# NANO103AE_v1 register map
File version: 1.0
Registers are 32-bit, read-write, reset 0x0 unless marked. A register's access mark holds for its fields unless they carry their own. Offsets are from the block's base; [hi:lo] are bit positions; {n}, {i} and the like mark numbered series; 'fields as' and 'values as' point back to an identical list.

## SYS — SYS Register Map
Base 0x50000000
0x00 SYS_PDID ro reset 0x110000 (reset mask 0xFFFF0000) — Part Device Identification Number Register
  [31:0] PDID — Part Device Identification Number (Read Only). This register reflects device part number code. Software can read this register to identify which device is used.
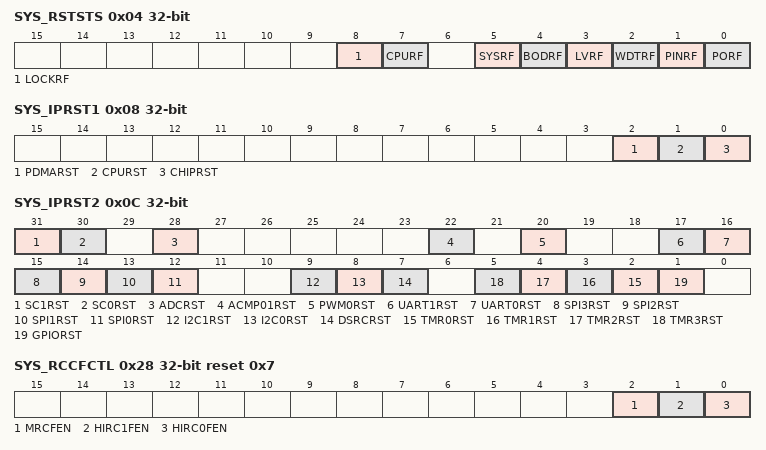
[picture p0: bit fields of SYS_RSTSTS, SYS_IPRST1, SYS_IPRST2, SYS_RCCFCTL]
0x04 SYS_RSTSTS (reset mask 0xFFFFFF00) — System Reset Status Register
  [8] LOCKRF — Lockup Reset Flag
    0=No reset from Cortex-M0; 1=The Cortex-M0 had issued the reset signal to reset the system by Cortex-M0 lockup event
  [7] CPURF — CPU Reset Flag. The CPU reset flag is set by hardware if software writes CPURST (SYS_IPRST0[1]) 1 to reset Cortex-M0 Core and Flash Memory Controller (FMC). Note: Write 1 to clear this bit to 0.
    0=No reset from CPU; 1=The Cortex-M0 Core and FMC are reset by software setting CPURST to 1
  [5] SYSRF — System Reset Flag. The system reset flag is set by the "Reset Signal" from the Cortex-M0 Core to indicate the previous reset source. Note: Write 1 to clear this bit to 0.
    0=No reset from Cortex-M0; 1=The Cortex-M0 had issued the reset signal to reset the system by writing 1 to the bit SYSRESETREQ(AIRCR[2], Application Interrupt and Reset Control Register, address = 0xE000ED0C) in system control registers of Cortex-M0 core
  [4] BODRF — BOD Reset Flag. The BOD reset flag is set by the "Reset Signal" from the Brown-Out Detector to indicate the previous reset source. Note: Write 1 to clear this bit to 0.
    0=No reset from BOD; 1=The BOD had issued the reset signal to reset the system
  [3] LVRF — LVR Reset Flag. The LVR reset flag is set by the "Reset Signal" from the Low-VoltageReset controller to indicate the previous reset source. Note: Write 1 to clear this bit to 0.
    0=No reset from LVR; 1=The LVR had issued the reset signal to reset the system
  [2] WDTRF — WDT Reset Flag. The WDT reset flag is set by the "Reset Signal" from the Watchdog Timer to indicate the previous reset source. Note: Write 1 to clear this bit to 0.
    0=No reset from watchdog timer or window watchdog timer; 1=The watchdog timer had issued the reset signal to reset the system
  [1] PINRF — NRESET Pin Reset Flag. The nRESET pin reset flag is set by the "Reset Signal" from the nRESET Pin to indicate the previous reset source. Note: Write 1 to clear this bit to 0.
    0=No reset from nRESET pin; 1=Pin nRESET had issued the reset signal to reset the system
  [0] PORF — POR Reset Flag. The POR reset flag is set by the "Reset Signal" from the Power-on Reset (POR) Controller or bit CHIPRST (SYS_IPRST0[0]) to indicate the previous reset source. Note: Write 1 to clear this bit to 0.
    0=No reset from POR or CHIPRST; 1=Power-on Reset (POR) or CHIPRST had issued the reset signal to reset the system
0x08 SYS_IPRST1 — Peripheral Reset Control Resister1
  [2] PDMARST — PDMA Controller Reset (Write Protect). Setting this bit to 1 will generate a reset signal to the PDMA. User needs to set this bit to 0 to release from reset state. Note:This bit is write protected. Refer to the SYS_REGLCTL register.
    0=PDMA controller normal operation; 1=PDMA controllerreset
  [1] CPURST — Processor Core One-shot Reset (Write Protect). Setting this bit will only reset the processor core and Flash Memory Controller(FMC), and this bit will automatically return to 0 after the 2 clock cycles. Note:This bit is write protected. Refer to the SYS_REGLCTL register.
    0=Processor core normal operation; 1=Processor core one-shot reset
  [0] CHIPRST — Chip One-shot Reset (Write Protect). Setting this bit will reset the whole chip, including Processor core and all peripherals, and this bit will automatically return to 0 after the 2 clock cycles. The CHIPRST is same as the POR reset, all the chip controllers is reset and the chip setting from flash are also reload. About the difference between CHIPRST and SYSRESETREQ(AIRCR[2]), please refer to section 6.2.2. Note:This bit is write protected. Refer to the SYS_REGLCTL register.
    0=Chip normal operation; 1=Chip one-shot reset
0x0C SYS_IPRST2 — Peripheral Reset Control Resister2
  [31] SC1RST — SmartCard1 Controller Reset
    0=SmartCardmodule normal operation; 1=SmartCardmodule reset
  [30] SC0RST — SmartCard0 Controller Reset
    0=SmartCardmodule normal operation; 1=SmartCardmodule reset
  [28] ADCRST — ADC Controller Reset
    0=ADC module normal operation; 1=ADC module reset
  [22] ACMP01RST — Comparator Controller Reset
    0=Comparatormodule normal operation; 1=Comparatormodule reset
  [20] PWM0RST — PWM0 Controller Reset
    0=PWM0 module normal operation; 1=PWM0 module reset
  [17] UART1RST — UART1 Controller Reset
    0=UART1 module normal operation; 1=UART1 module reset
  [16] UART0RST — UART0 Controller Reset
    0=UART0 module normal operation; 1=UART0 module reset
  [15] SPI3RST — SPI3 Controller Reset
    0=SPI3module normal operation; 1=SPI3modulereset
  [14] SPI2RST — SPI2 Controller Reset
    0=SPI2module normal operation; 1=SPI2modulereset
  [13] SPI1RST — SPI1 Controller Reset
    0=SPI1 module normal operation; 1=SPI1 modulereset
  [12] SPI0RST — SPI0 Controller Reset
    0=SPI0 module normal operation; 1=SPI0 module reset
  [9] I2C1RST — I2C1 Controller Reset
    0=I2C1 module normal operation; 1=I2C1 module reset
  [8] I2C0RST — I2C0 Controller Reset
    0=I2C0 module normal operation; 1=I2C0 module reset
  [7] DSRCRST — DSRC Controller Reset
    0=DSRCmodule normal operation; 1=DSRCmodule reset
  [n+2] TMR{n}RST (n=0..3) — Timer{n} Controller Reset
    0=Timer{n} module normal operation; 1=Timer{n} module reset
  [1] GPIORST — GPIO Controller Reset
    0=GPIO module normal operation; 1=GPIO module reset
0x20 SYS_TEMPCTL — Temperature Sensor Control Register
  [0] VTEMPEN — Temperature Sensor Enable Bit. This bit is used to enable/disable temperature sensor function.
    0=Temperature sensor function Disabled (default); 1=Temperature sensor function Enabled
0x28 SYS_RCCFCTL reset 0x7 — RC Clock Filter Control Register
  [2] MRCFEN — MRC Clock Filter Enable Bit. This bit is used to enable/disable MRC clock filter function.
    0=4MHz MRC clock filter function Disabled; 1=4MHz MRC clock filter function Enabled (default)
  [1] HIRC1FEN — HIRC1 Clock Filter Enable Bit. This bit is used to enable/disable HIRC1clock filter function.
    0=HIRC1clock filter function Disabled; 1=HIRC1clock filter function Enabled (default)
  [0] HIRC0FEN — HIRC0 Clock Filter Enable Bit. This bit is used to enable/disable HIRC0clock filter function.
    0=HIRC0clock filter function Disabled; 1=HIRC0clock filter function Enabled (default)
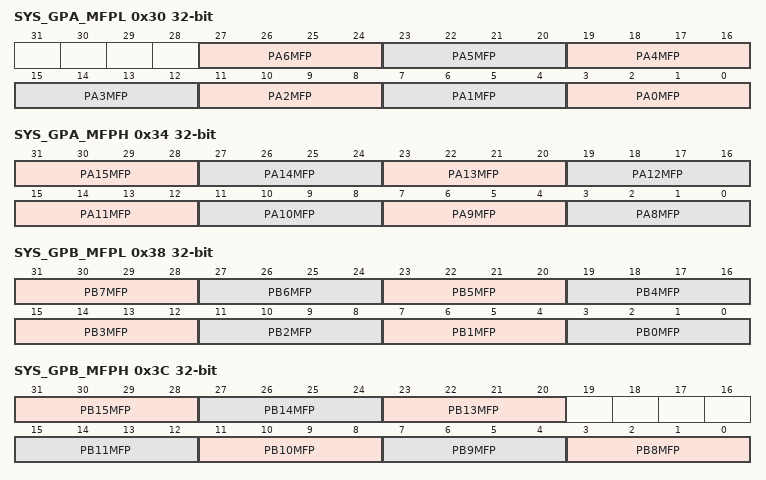
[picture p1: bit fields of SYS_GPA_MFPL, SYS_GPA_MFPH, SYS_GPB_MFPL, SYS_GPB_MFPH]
0x30 SYS_GPA_MFPL — GPIOA Low Byte Multiple Function Control Register
  [27:24] PA6MFP — PA.6 Multi-function Pin Selection
    0=GPIOA[6]; 1=ADC analog input6; 2=Comparator1 output; 3=Timer3 capture input; 4=Timer3 external counter input; 5=PWM0 channel3 output/capture input; 7=Timer3 toggle output
  [23:20] PA5MFP — PA.5 Multi-function Pin Selection
    0=GPIOA[5]; 1=ADC analog input5; 5=I2C0 clock pin; 6=SPI3 serial clock pin
  [19:16] PA4MFP — PA.4 Multi-function Pin Selection
    0=GPIOA[4]; 1=ADC analog input4; 5=I2C0 data input/output pin; 6=SPI31stMISO (Master In, Slave Out) pin
  [15:12] PA3MFP — PA.3 Multi-function Pin Selection
    0=GPIOA[3]; 1=ADC analog input3; 5=Data transmitter output pin for UART1; 6=SPI31stMOSI (Master Out, Slave In) pin
  [11:8] PA2MFP — PA.2 Multi-function Pin Selection
    0=GPIOA[2]; 1=ADC analog input2; 5=Data receiver input pin for UART1
  [7:4] PA1MFP — PA.1 Multi-function Pin Selection
    0=GPIOA[1]; 1=ADC analog input1; 2=Comparator1 N-end input; 6=SPI0 2ndMISO (Master In, Slave Out) pin
  [3:0] PA0MFP — PA.0 Multi-function Pin Selection
    0=GPIOA[0]; 1=ADC analog input0; 2=Comparator1 P-end input; 3=Timer0 capture input; 5=PWM0 channel2 output/capture input
0x34 SYS_GPA_MFPH — GPIOA High Byte Multiple Function Control Register
  [31:28] PA15MFP — PA.15 Multi-function Pin Selection
    0=GPIOA[15]; 1=PWM0 channel3 output/capture input; 2=I2C1 clock pin; 3=Timer1 capture input; 4=SmartCard0 power pin; 6=Data transmitter output pin for UART0; 7=Timer3 toggle output
  [27:24] PA14MFP — PA.14 Multi-function Pin Selection
    0=GPIOA[14]; 1=PWM0 channel2 output/capture input; 2=I2C1 data input/output pin; 3=I2C1 data input/output pin; 5=Timer2 external counter input; 6=Data receiver input pin for UART0; 7=Timer2 toggle output
  [23:20] PA13MFP — PA.13 Multi-function Pin Selection
    0=GPIOA[13]; 1=PWM0 channel1 output/capture input; 3=Timer1 capture input; 5=I2C0 clock pin
  [19:16] PA12MFP — PA.12 Multi-function Pin Selection
    0=GPIOA[12]; 1=PWM0 channel0 output/capture input; 3=Timer0 capture input; 5=I2C0 data input/output pin
  [15:12] PA11MFP — PA.11 Multi-function Pin Selection
    0=GPIOA[11]; 1=I2C1 clock pin; 2=Timer3 external counter input; 3=SmartCard0 reset pin; 4=SPI21stMOSI (Master Out, Slave In) pin; 5=Timer3 toggle output
  [11:8] PA10MFP — PA.10 Multi-function Pin Selection
    0=GPIOA[10]; 1=I2C1 data input/output pin; 2=Timer2 external counter input; 3=SmartCard0 power pin; 4=SPI21stMISO (Master In, Slave Out) pin; 5=Timer2 toggle output
  [7:4] PA9MFP — PA.9 Multi-function Pin Selection
    0=GPIOA[9]; 1=I2C0 clock pin; 2=Timer1 external counter input; 3=SmartCard0 data pin; 4=SPI0 serial clock pin; 5=Timer1 toggle output; 6=UART1 Request to Send output pin; 7=Snooper pin
  [3:0] PA8MFP — PA.8 Multi-function Pin Selection
    0=GPIOA[8]; 1=I2C0 data input/output pin; 2=Timer0 external counter input; 3=SmartCard0 clock pin; 4=SPI2 slave select pin; 5=Timer0 toggle output; 6=UART0 Clear to Send input pin
0x38 SYS_GPB_MFPL — GPIOB Low Byte Multiple Function Control Register
  [31:28] PB7MFP — PB.7 Multi-function Pin Selection
    0=GPIOB[7]; 1=UART1 Clear to Send input pin
  [27:24] PB6MFP — PB.6 Multi-function Pin Selection
    0=GPIOB[6]; 1=UART1 Request to Send output pin; 4=SPI21stMISO (Master In, Slave Out) pin
  [23:20] PB5MFP — PB.5 Multi-function Pin Selection
    0=GPIOB[5]; 1=Data transmitter output pin for UART1; 3=SmartCard0 reset pin; 4=SPI2 serial clock pin
  [19:16] PB4MFP — PB.4 Multi-function Pin Selection
    0=GPIOB[4]; 1=Data receiver input pin for UART1; 3=SmartCard0 card detect pin; 4=SPI2 slave select pin; 6=RTC 1Hz output
  [15:12] PB3MFP — PB.3 Multi-function Pin Selection
    0=GPIOB[3]; 1=UART0 Clear to Send input pin; 3=SPI1 slave select pin; 4=SmartCard1 card detect pin
  [11:8] PB2MFP — PB.2 Multi-function Pin Selection
    0=GPIOB[2]; 1=UART0 Request to Send output pin; 3=SPI1 serial clock pin; 4=Frequency Divider output pin
  [7:4] PB1MFP — PB.1 Multi-function Pin Selection
    0=GPIOB[1]; 1=Data transmitter output pin for UART0; 3=SPI11stMISO (Master In, Slave Out) pin
  [3:0] PB0MFP — PB.0 Multi-function Pin Selection
    0=GPIOB[0]; 1=Data receiver input pin for UART0; 3=SPI11stMOSI (Master Out, Slave In) pin
0x3C SYS_GPB_MFPH — GPIOB High Byte Multiple Function Control Register
  [31:28] PB15MFP — PB.15 Multi-function Pin Selection
    0=GPIOB[15]; 1=External interrupt1 input pin; 3=Snooper pin; 4=SmartCard1 card detect pin
  [27:24] PB14MFP — PB.14 Multi-function Pin Selection
    0=GPIOB[14]; 1=External interrupt0 input pin; 3=SPI22ndMOSI (Master Out, Slave In) pin; 4=SPI2 slave select pin
  [23:20] PB13MFP — PB.13 Multi-function Pin Selection
    0=GPIOB[13]; 3=SPI22ndMISO (Master In, Slave Out) pin; 7=Snooper pin
  [15:12] PB11MFP — PB.11 Multi-function Pin Selection
    0=GPIOB[11]; 1=PWM0 channel4 output/capture input; 2=Timer3 external counter input; 4=Timer3 toggle output; 5=SPI0 1stMISO (Master In, Slave Out) pin
  [11:8] PB10MFP — PB.10 Multi-function Pin Selection
    0=GPIOB[10]; 1=SPI0 1stMOSI (Master Out, Slave In) pin; 4=Timer2 toggle output; 5=SPI0 slave select pin
  [7:4] PB9MFP — PB.9 Multi-function Pin Selection
    0=GPIOB[9]; 1=SPI1 slave select pin; 2=Timer2 external counter input; 4=Timer2 toggle output; 5=External interrupt0 input pin
  [3:0] PB8MFP — PB.8 Multi-function Pin Selection
    0=GPIOB[8]; 1=ADC external trigger input; 2=Timer0 external counter input; 3=External interrupt0 input pin; 4=Timer0 toggle output; 7=Snooper pin
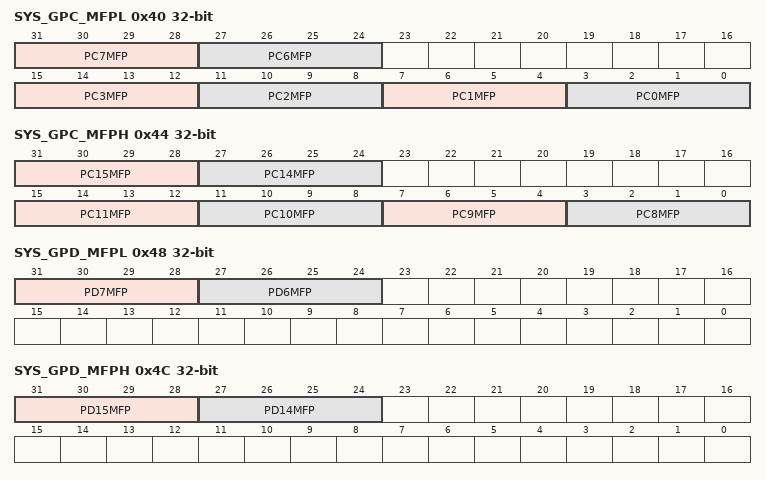
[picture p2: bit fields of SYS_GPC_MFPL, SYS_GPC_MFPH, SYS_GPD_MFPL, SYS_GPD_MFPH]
0x40 SYS_GPC_MFPL — GPIOC Low Byte Multiple Function Control Register
  [31:28] PC7MFP — PC.7 Multi-function Pin Selection
    0=GPIOC[7]; 1=Data transmitter output pin for UART1; 2=ADC analog input7; 3=Timer1 capture input; 5=PWM0 channel1 output/capture input
  [27:24] PC6MFP — PC.6 Pin Fuction Selection
    0=GPIOC[6]; 1=Data receiver input pin for UART1; 3=Timer0 capture input; 4=SmartCard1 card detect pin; 5=PWM0 channel0 output/capture input
  [15:12] PC3MFP — PC.3 Multi-function Pin Selection
    0=GPIOC[3]; 1=SPI0 1stMOSI (Master Out, Slave In) pin; 4=SmartCard1 reset pin; 5=PWM0 break0 input 0
  [11:8] PC2MFP — PC.2 Multi-function Pin Selection
    0=GPIOC[2]; 1=SPI0 1st MISO (Master In, Slave Out) pin; 4=SmartCard1 power pin; 5=PWM0 break0 input 1
  [7:4] PC1MFP — PC.1 Multi-function Pin Selection
    0=GPIOC[1]; 1=SPI0 serial clock pin; 4=SmartCard1 data pin; 5=PWM0 break1 input 0
  [3:0] PC0MFP — PC.0 Multi-function Pin Selection
    0=GPIOC[0]; 1=SPI0 slave select pin; 4=SmartCard1 clock pin; 5=PWM0 break1 input 1
0x44 SYS_GPC_MFPH — GPIOC High Byte Multiple Function Control Register
  [31:28] PC15MFP — PC.15 Multi-function Pin Selection
    0=GPIOC[15]; 1=UART1 Request to Send output pin; 3=Timer0 capture input
  [27:24] PC14MFP — PC.14 Multi-function Pin Selection
    0=GPIOC[14]; 1=UART0 Clear to Send input pin
  [15:12] PC11MFP — PC.11 Multi-function Pin Selection
    0=GPIOC[11]; 1=SPI1 1stMOSI (Master Out, Slave In) pin; 5=Data transmitter output pin for UART1
  [11:8] PC10MFP — PC.10 Multi-function Pin Selection
    0=GPIOC[10]; 1=SPI0 1stMISO (Master In, Slave Out) pin; 5=Data receiver input pin for UART1
  [7:4] PC9MFP — PC.9 Multi-function Pin Selection
    0=GPIOC[9]; 1=SPI1 serial clock pin; 5=I2C1 clock pin
  [3:0] PC8MFP — PC.8 Multi-function Pin Selection
    0=GPIOC[8]; 1=SPI1 slave select pin; 5=I2C1 data input/output pin
0x48 SYS_GPD_MFPL — GPIOD Low Byte Multiple Function Control Register
  [31:28] PD7MFP — PD.7 Multi-function Pin Selection
    0=GPIOD[7]; 3=SPI12ndMISO (Master In, Slave Out) pin; 4=SmartCard1 power pin
  [27:24] PD6MFP — PD.6 Multi-function Pin Selection
    0=GPIOD[6]; 3=SPI12ndMOSI (Master Out, Slave In) pin; 4=SmartCard1 reset pin
0x4C SYS_GPD_MFPH — GPIOD High Byte Multiple Function Control Register
  [31:28] PD15MFP — PD.15 Multi-function Pin Selection
    0=GPIOD[15]; 1=SPI0 2ndMISO (Master In, Slave Out) pin; 4=SmartCard1 clock pin
  [27:24] PD14MFP — PD.14 Multi-function Pin Selection
    0=GPIOD[14]; 1=SPI0 2ndMOSI (Master Out, Slave In) pin
0x50 SYS_GPE_MFPL — GPIOE Low Byte Multiple Function Control Register
  [23:20] PE5MFP — PE.5 Multi-function Pin Selection
    0=GPIOE[5]; 1=PWM0 channel5 output/capture input; 6=RTC 1Hz output
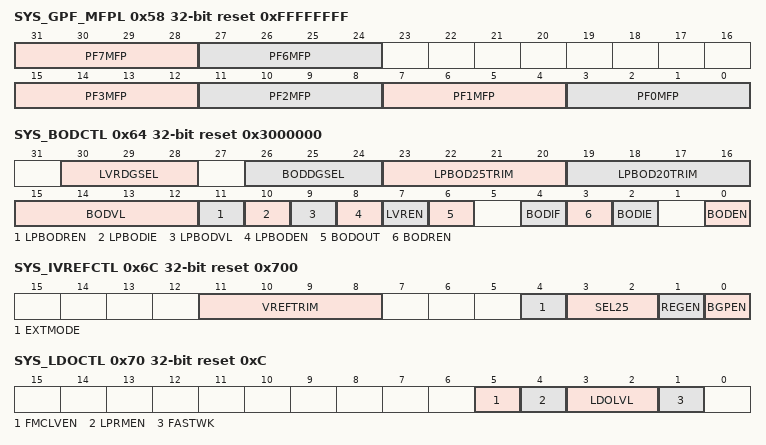
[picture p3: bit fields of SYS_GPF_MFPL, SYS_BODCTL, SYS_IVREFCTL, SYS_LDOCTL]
0x58 SYS_GPF_MFPL reset 0xFFFFFFFF — GPIOF Low Byte Multiple Function Control Register
  [31:28] PF7MFP — PF.7 Multi-function Pin Selection
    0=GPIOF[7]. External 32.768 kHz crystal input pin(default); 1=I2C1 clock pin; 3=SmartCard0 card detect pin
  [27:24] PF6MFP — PF.6 Multi-function Pin Selection
    0=GPIOF[6]. External 32.768 kHz crystal output pin(default); 1=I2C1 data input/output pin
  [15:12] PF3MFP — PF.3 Multi-function Pin Selection
    0=GPIOF[3]. External 4~36 MHz (high speed) crystal input pin
  [11:8] PF2MFP — PF.2 Multi-function Pin Selection
    0=GPIOF[2]. External 4~36 MHz (high speed) crystal output pin
  [7:4] PF1MFP — PF.1 Multi-function Pin Selection
    0=GPIOF[1]. Serial wired debugger clock pin; 4=Frequency Divider output pin; 5=External interrupt1 input pin
  [3:0] PF0MFP — PF.0 Multi-function Pin Selection
    0=GPIOF[1]. Serial wired debugger data pin; 5=External interrupt0 input pin
0x60 SYS_PORCTL — Power-on-Reset Controller Register
  [15:0] POROFF — Power-on Reset Enable Bit (Write Protect). When powered on, the POR circuit generates a reset signal to reset the whole chip function, but noise on the power may cause the POR active again. User can disable internal POR circuit to avoid unpredictable noise to cause chip reset by writing 0x5AA5 to this field. The POR function will be active again when this field is set to another value or chip is reset by other reset source, including: nRESET, Watchdog, BOD reset, ICE reset command and the software-chip reset function. Note:This bit is write protected. Refer to the SYS_REGLCTL register.
0x64 SYS_BODCTL reset 0x3000000 (reset mask 0xFF000F00) — Brown-out Detector Controller Register
  [30:28] LVRDGSEL — LVR Output De-glitch Time Select (Write Protect). Note: These bits are write protected. Refer to the SYS_REGLCTL register.
    0=Without de-glitch function; 1=4 system clock (HCLK); 2=8 system clock (HCLK); 3=16 system clock (HCLK); 4=32 system clock (HCLK); 5=64 system clock (HCLK); 6=128 system clock (HCLK); 7=256 system clock (HCLK)
  [26:24] BODDGSEL — Brown-out Detector Output De-glitch Time Select (Write Protect). Note: These bits are write protected. Refer to the SYS_REGLCTL register.
    0=BOD output is sampled by RC10K clock; 1=4 system clock (HCLK); 2=8 system clock (HCLK); 3=16 system clock (HCLK); 4=32 system clock (HCLK); 5=64 system clock (HCLK); 6=128 system clock (HCLK); 7=256 system clock (HCLK)
  [23:20] LPBOD25TRIM — Low Power BOD 2.5 TRIM Value(Write Protect). This value is used to control LPBOD25 detect voltage level in power-down mode, nominal 2.5 V. Higher trim value, higher detection voltage. Note: These bits are write protected. Refer to the SYS_REGLCTL register.
  [19:16] LPBOD20TRIM — Low Power BOD 2.0 TRIM Value(Write Protect). This value is used to control BOD20 detect voltage level in power-down mode, nominal 2.0 V. Higher trim value, higher detection voltage. Note: These bits are write protected. Refer to the SYS_REGLCTL register.
  [15:12] BODVL — Brown-out Detector Threshold Voltage Selection (Write Protect). The default value is set by flash controller user configuration register CBOV (CONFIG0[]). Note: This bit is write protected. Refer to the SYS_REGLCTL register.
    0=Brown-Out Detector threshold voltageis 1.7V; 1=Brown-Out Detector threshold voltageis 1.8V; 2=Brown-Out Detector threshold voltageis 1.9V; 3=Brown-Out Detector threshold voltageis 2.0V; 4=Brown-Out Detector threshold voltageis 2.1V; 5=Brown-Out Detector threshold voltageis 2.2V; 6=Brown-Out Detector threshold voltageis 2.3V; 7=Brown-Out Detector threshold voltageis 2.4V; 8=Brown-Out Detector threshold voltageis 2.5V; 9=Brown-Out Detector threshold voltageis 2.6V; 10=Brown-Out Detector threshold voltageis 2.7V; 11=Brown-Out Detector threshold voltageis 2.8V; 12=Brown-Out Detector threshold voltageis 2.9V; 13=Brown-Out Detector threshold voltageis 3.0V; 14=Brown-Out Detector threshold voltageis 3.1V
  [11] LPBODREN — Low Power Brown-out Reset Enable Bit (Write Protect). Low Power Brown-out Dector only valid in Power-down mode. Note1: While the Low power Brown-out Detector function is enabled (LPBODEN high) and LPBOD reset function is enabled (LPBODREN high), LPBOD will assert a signal to reset chip when the detected voltage is lower than the threshold (BODOUT high). Note2: This bit is write protected. Refer to the SYS_REGLCTL register.
    0=Low power Brown-out dector "RESET" function Disabled in Power-down mode; 1=Low Power Brown-out dector "RESET" function Enabled in Power-down mode
  [10] LPBODIE — Low Power BOD Interrupt Enable Control(Write Protect). Low Power Brown-out Dector only valid in Power-down mode. Note1: While the LPBOD function is enabled (LPBODEN high) and LPBOD interrupt function is enabled (LPBODIEhigh), LPBOD will assert an interrupt if BODOUT is high. Note2: This bit is write protected. Refer to the SYS_REGLCTL register.
    0=Interrupt does not issue when LPBOD occurs in Power-down mode; 1=Interrupt issues when LPBOD occurs in Power-down mode
  [9] LPBODVL — Low Power Brown-out Detector Threshold Voltage Selection(Write Protect). Low Power Brown-out Dector only valid in Power-down mode. Note1: This bit is write protected. Refer to the SYS_REGLCTL register.
    0=Low Power Brown-Out Detector threshold voltageis 2.0V in Power-down mode; 1=Low Power Brown-Out Detector threshold voltageis 2.5V in Power-down mode
  [8] LPBODEN — Low Power Brown-out Detector Enable Bit (Write Protect). Low Power Brown-out Dector only valid in Power-down mode. Note1: This bit is write protected. Refer to the SYS_REGLCTL register. Note2: LIRC must be enabled before enable BOD.
    0=Low Power Brown-out Detector function Disabled in Power-down mode; 1=Low Power Brown-out Detector function Enabled in Power-down mode
  [7] LVREN — Low Voltage Reset Enable Bit (Write Protect). The LVR function resets the chip when the input power voltage is lower than LVR circuit setting. LVR function is enabled by default. Note1: After enabling the bit, the LVR function will be active with 100us delay for LVR output stable (default). Note2: This bit is write protected. Refer to the SYS_REGLCTL register. Note3: LIRC must be enabled before enable LVR.
    0=Low Voltage Reset function Disabled; 1=Low Voltage Reset function Enabled
  [6] BODOUT — Brown-out DetectorOutuput Status. It means the detected voltage is lower than BODVL setting. If the BODEN is 0, BOD function disabled , this bit always responds 0. Note: This bit is ready-only.
    0=Brown-out Detector output status is 0; 1=Brown-out Detector output status is 1
  [4] BODIF — Brown-out DetectorInterrupt Flag. Note: Write 1 to clear this bit to 0.
    0=Brown-out Detector does not detect any voltage drift at VDD down through or up through the target detected voltage after interrupt is enabled; 1=When Brown-out Detectordetects the VDD is dropped down through the target detected voltage or the VDD is raised up through the target detected voltage, this bit is set to 1 and the brown-out interrupt is requested if brown-out interrupt is enabled
  [3] BODREN — Brown-out Reset Enable Bit (Write Protect). The default value is set by flash controller user configuration register CBOV(CONFIG0[]) bit. Note1: While the Brown-out Detector function is enabled (BODEN high) and BOD reset function is enabled (BODRSTEN high), BOD will assert a signal to reset chip when the detected voltage is lower than the threshold (BODOUT high). Note2: This bit is write protected. Refer to the SYS_REGLCTL register.
    0=Brown-out "RESET" function Disabled in Normal Mode; 1=Brown-out "RESET" function Enabled in Normal Mode
  [2] BODIE — BOD Interrupt Enable Control(Write Protect). Note1: While the BOD function is enabled (BODEN high) and BOD interrupt function is enabled (BODRSTEN low), BOD will assert an interrupt if BODOUT is high. Note2: This bit is write protected. Refer to the SYS_REGLCTL register.
    0=Interrupt does not issue when BOD occurs in Normal Mode; 1=Interrupt issues when BOD occursi in Normal Mode
  [0] BODEN — Brown-out Detector Enable Bit (Write Protect). The default value is set by flash controller user configuration register CBODEN (CONFIG0 []).This Brown-out Detecto only valid in Normal Mode. Note1: This bit is write protected. Refer to the SYS_REGLCTL register. Note2: LIRC must be enabled before enable BOD.
    0=Brown-out Detector function Disabled in Normal mode; 1=Brown-out Detector function Enabled in Normal mode
0x68 SYS_BODSTS ro — Brown-out Detector Status Register
0x6C SYS_IVREFCTL reset 0x700 — Internal Voltage Reference Control Register
  [11:8] VREFTRIM — Internal Voltage Reference Trim(Write Protect). Note: This bit is write protected. Refer to the SYS_REGLCTL register.
  [4] EXTMODE — Regulator External Mode(Write Protect). Users can output regulator output voltage in VREF pin if EXT_MODE is high. Note: This bit is write protected. Refer to the SYS_REGLCTL register.
    0=No connection with external VREF pin; 1=Connet to external VREF pin. Connect a 1uF to 10uF capacitor to AVSS will let internal voltage reference be more stable
  [3:2] SEL25 — Regulator Output Voltage Selection(Write Protect). Select internal reference voltage level. Note: This bit is write protected. Refer to the SYS_REGLCTL register.
    0=1.5V; 1=1.8V; 2=2.5V; 3=2.5V
  [1] REGEN — Regulator Enable Control(Write Protect). Enable internal 1.5, 1.8V or 2.5V reference voltage. Note: This bit is write protected. Refer to the SYS_REGLCTL register.
    0=Regulator Disabled; 1=Regulator Enabled
  [0] BGPEN — Band-gap Enable Control(Write Protect). Band-gap is the reference voltage of internal reference voltage. User must enable band-gap if want to enable internal 1.5, 1.8V or 2.5V reference voltage. Note: This bit is write protected. Refer to the SYS_REGLCTL register.
    0=Band-gap Disabled; 1=Band-gap Enabled
0x70 SYS_LDOCTL reset 0xC — LDO Control Register
  [5] FMCLVEN — Flash Memory Low Voltage Mode Enable Bit (Write Protect). Note: This bit is write protected. Refer to the SYS_REGLCTL register.
    0=Flash memory low voltage(1.2V) mode Enabled; 1=Flash memory low voltage(1.2V) mode Disabled
  [4] LPRMEN — Low-power Run Mode Enable Bit (Write Protect). Note: This bit is write protected. Refer to the SYS_REGLCTL register.
    0=Low-Power runmode Enabled; 1=Low-Power runmode Disabled
  [3:2] LDOLVL — LDO Output Voltage Select(Write Protect). Note: This bit is write protected. Refer to the SYS_REGLCTL register.
    0=1.2V; 1=1.6V; 2=1.8V; 3=1.8V
  [1] FASTWK — Fast Wake-up Control Bit (Write Protect). Note: This bit is write protected. Refer to the SYS_REGLCTL register.
    0=Fast Wake-up from Power-Down mode Disabled; 1=Fast Wake-up from Power-Down mode Enabled
0x74 SYS_BATDCTL — Battery Voltage Divider Control Register
  [0] BATDIV2EN — Battery Voltageg Divide 2 Enable Bit. This bit is used to enable/disable battery voltageg divider function.
    0=Battery voltageg divide 2 function Disabled (default); 1=Battery voltageg divide 2 function Enabled
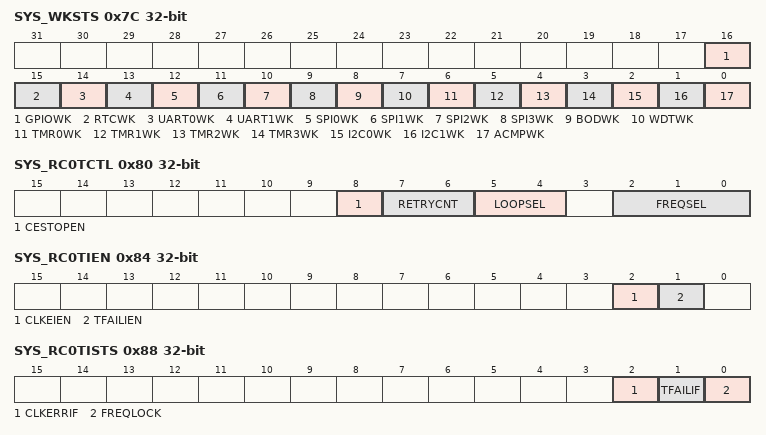
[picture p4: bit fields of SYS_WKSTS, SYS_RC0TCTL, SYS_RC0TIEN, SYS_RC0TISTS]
0x7C SYS_WKSTS ro — System Wake-up Status Register
  [16] GPIOWK — GPIO Wake-up Flag (Read Only). This flag indicates that wake-up of device from Power-down mode was requested with GPIO wake-up event. This flag is cleared when Power-down mode is entered.
  [15] RTCWK — RTC Wake-up Flag (Read Only). This flag indicates that wake-up of device from Power-down mode was requested with a RTCalarm or tick time happened. This flag is cleared when Power-down mode is entered.
  [14] UART0WK — UART0 Wake-up Flag (Read Only). This flag indicates that wake-up of device from Power-down mode was requested with UART0 wake-up event. This flag is cleared when Power-down mode is entered.
  [13] UART1WK — UART1 Wake-up Flag (Read Only). This flag indicates that wake-up of device from Power-down mode was requested with UART1 wake-up event. This flag is cleared when Power-down mode is entered.
  [12-n] SPI{n}WK (n=0..3) — SPI{n} Wake-up Flag (Read Only). This flag indicates that wake-up of device from Power-down mode was requested with SPI{n} wake-up event. This flag is cleared when Power-down mode is entered.
  [8] BODWK — BOD Wake-up Flag (Read Only). This flag indicates that wake-up of device from Power-down mode was requested with BOD wake-up event. This flag is cleared when Power-down mode is entered.
  [7] WDTWK — WDT Wake-up Flag (Read Only). This flag indicates that wake-up of device from Power-down mode was requested with WDT wake-up event. This flag is cleared when Power-down mode is entered.
  [6-n] TMR{n}WK (n=0..3) — TMR{n} Wake-up Flag (Read Only). This flag indicates that wake-up of device from Power-down mode was requested withTMR{n} wake-up event. This flag is cleared when Power-down mode is entered.
  [2] I2C0WK — I2C0 Wake-up Flag (Read Only). This flag indicates that wake-up of device from Power-down mode was requested with I2C0 wake-up event. This flag is cleared when Power-down mode is entered.
  [1] I2C1WK — I2C1 Wake-up Flag (Read Only). This flag indicates that wake-up of device from Power-down mode was requested with I2C1 wake-up event. This flag is cleared when Power-down mode is entered.
  [0] ACMPWK — ACMP Wake-up Flag (Read Only). This flag indicates that wake-up of device from Power-down mode was requested with ACMP wake-up event. This flag is cleared when Power-down mode is entered.
0x80 SYS_RC0TCTL — HIRC0 Trim Control Register
  [8] CESTOPEN — Clock Error Stop Enable Bit. This bit is used to control if stop the HIRC0 trim operation when 32.768 kHz clock error is detected. If set this bit high and 32.768 kHz clock error detected, the status CLKERRIF (SYS_IRC0TISTS[2]) would be set high and HIRC0 trim operation was stopped. If this bit is low and 32.768 kHz clock error detected, the status CLKERRIF (SYS_IRC0TISTS[2]) would be set high and HIRC0 trim operation is continuously.
    0=The trim operation is keep going if clock is inaccuracy; 1=The trim operation is stopped if clock is inaccuracy
  [7:6] RETRYCNT — Trim Value Update Limitation Count. This field defines that how many times the auto trim circuit will try to update the HIRC0 trim value before the frequency of HIRC0 locked. Once the HIRC0 locked, the internal trim value update counter will be reset. If the trim value update counter reached this limitation value and frequency of HIRC0 still doesn't lock, the auto trim operation will be disabled and FREQSEL (SYS_IRC0TCTL[1:0]) will be cleared to 00.
    0=Trim retry count limitation is 64 loops; 1=Trim retry count limitation is 128 loops; 2=Trim retry count limitation is 256 loops; 3=Trim retry count limitation is 512 loops
  [5:4] LOOPSEL — Trim Calculation Loop Selection. This field defines that trim value calculation is based on how many 32.768 kHz clock. Note: For example, if LOOPSEL is set as 00, auto trim circuit will calculate trim value based on the average frequency difference in 4 32.768 kHz clock.
    0=Trim value calculation is based on average difference in 4 32.768 kHz clock; 1=Trim value calculation is based on average difference in 8 32.768 kHz clock; 2=Trim value calculation is based on average difference in 16 32.768 kHz clock; 3=Trim value calculation is based on average difference in 32 32.768 kHz clock
  [2:0] FREQSEL — Trim Frequency Selection. This field indicates the target frequency of 12 MHz internal high speed RC oscillator (HIRC0) auto trim. During auto trim operation, if clock error detected with CESTOPEN (SYS_IRC0TCTL[8]) is set to 1 or trim retry limitation count reached, this field will be cleared to 000 automatically. Note: HIRC0 auto trim cannot work normally inPower-down mode. These bits must be cleared before entering Power-down mode.
    0=Disable HIRC0 auto trim function; 1=Enable HIRC0 auto trim function and trim HIRC to 11.0592 MHz; 2=Enable HIRC0 auto trim function and trim HIRC to 12 MHz; 3=Enable HIRC0 auto trim function and trim HIRC to 12.288 MHz; 4=Enable HIRC0 auto trim function and trim HIRC to 16 MHz
0x84 SYS_RC0TIEN — HIRC0 Trim Interrupt Enable Register
  [2] CLKEIEN — Clock Error Interrupt Enable Bit. This bit controls if CPU would get an interrupt while clock is inaccuracy during auto trim operation. If this bit is set to1, and CLKERRIF(SYS_IRC0TSTS[2]) is set during auto trim operation, an interrupt will be triggered to notify the clock frequency is inaccuracy.
    0=Disable CLKERRIF(SYS_IRC0TSTS[2]) status to trigger an interrupt to CPU; 1=Enable CLKERRIF(SYS_IRC0TSTS[2]) status to trigger an interrupt to CPU
  [1] TFAILIEN — Trim Failure Interrupt Enable Bit. This bit controls if an interrupt will be triggered while HIRC0 trim value update limitation count reached and HIRC0 frequency still not locked on target frequency set by FREQSEL(SYS_IRC0TCTL[1:0]). If this bit is high and TFAILIF(SYS_IRC0TSTS[1]) is set during auto trim operation, an interrupt will be triggered to notify that HIRC0 trim value update limitation count was reached.
    0=Disable TFAILIF(SYS_IRC0TSTS[1]) status to trigger an interrupt to CPU; 1=Enable TFAILIF(SYS_IRC0TSTS[1]) status to trigger an interrupt to CPU
0x88 SYS_RC0TISTS — HIRC0 Trim Interrupt Status Register
  [2] CLKERRIF — Clock Error Interrupt Status. When the frequency of 32.768 kHz external low speed crystal oscillator (LXT) or internal high speed RC oscillator (HIRC0) is shift larger to unreasonable value, this bit will be set and to be an indicate that clock frequency is inaccuracy. Once this bit is set to 1, the auto trim operation stopped and FREQSEL(SYS_IRC0TCTL[1:0]) will be cleared to 00 by hardware automatically if CESTOPEN(SYS_IRC0TCTL[8]) is set to 1. If this bit is set and CLKEIEN(SYS_IRC0TIEN[2]) is high, an interrupt will be triggered to notify the clock frequency is inaccuracy. Write 1 to clear this to 0.
    0=Clock frequency is accuracy; 1=Clock frequency is inaccuracy
  [1] TFAILIF — Trim Failure Interrupt Status. This bit indicates that HIRC0 trim value update limitation count reached and the HIRC0 clock frequency still doesn't be locked. Once this bit is set, the auto trim operation stopped and FREQSEL(SYS_IRC0TCTL[1:0]) will be cleared to 00 by hardware automatically. If this bit is set and TFAILIEN(SYS_IRC0TIEN[1]) is high, an interrupt will be triggered to notify that HIRC0 trim value update limitation count was reached. Write 1 to clear this to 0.
    0=Trim value update limitation count does not reach; 1=Trim value update limitation count reached and HIRC frequency still not locked
  [0] FREQLOCK — HIRC0 Frequency Lock Status. This bit indicates the HIRC0 frequency is locked. This is a status bit and doesn't trigger any interrupt.
    0=The internal high-speed oscillator frequency doesn't lock at frequency set by FREQSEL (SYS_IRC0TCTL[2:0]); 1=The internal high-speed oscillator frequency locked at frequency set by FREQSEL (SYS_IRC0TCTL[2:0])
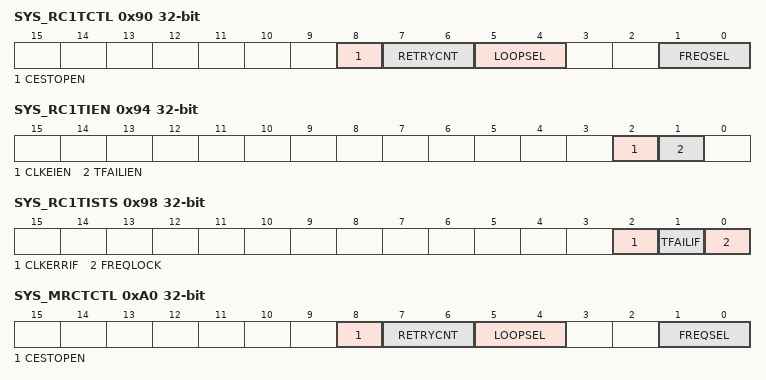
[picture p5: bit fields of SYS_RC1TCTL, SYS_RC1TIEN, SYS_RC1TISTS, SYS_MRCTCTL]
0x90 SYS_RC1TCTL — HIRC1 Trim Control Register
  [8] CESTOPEN — Clock Error Stop Enable Bit. This bit is used to control if stop the HIRC1 trim operation when 32.768 kHz clock error is detected. If set this bit high and 32.768 kHz clock error detected, the status CLKERRIF (SYS_IRC1TISTS[2]) would be set high and HIRC1 trim operation was stopped. If this bit is low and 32.768 kHz clock error detected, the status CLKERRIF (SYS_IRC1TISTS[2]) would be set high and HIRC1 trim operation is continuously.
    values as SYS_RC0TCTL.CESTOPEN
  [7:6] RETRYCNT — Trim Value Update Limitation Count. This field defines that how many times the auto trim circuit will try to update the HIRC1 trim value before the frequency of HIRC1 locked. Once the HIRC1 locked, the internal trim value update counter will be reset. If the trim value update counter reached this limitation value and frequency of HIRC1 still doesn't lock, the auto trim operation will be disabled and FREQSEL (SYS_IRC1TCTL[1:0]) will be cleared to 00.
    values as SYS_RC0TCTL.RETRYCNT
  [5:4] LOOPSEL — Trim Calculation Loop Selection. This field defines that trim value calculation is based on how many 32.768 kHz clock. Note: For example, if LOOPSEL is set as 00, auto trim circuit will calculate trim value based on the average frequency difference in 4 32.768 kHz clock.
    values as SYS_RC0TCTL.LOOPSEL
  [1:0] FREQSEL — Trim Frequency Selection. This field indicates the target frequency of 36 MHz internal high speed RC oscillator (HIRC1) auto trim. During auto trim operation, if clock error detected with CESTOPEN (SYS_IRC1TCTL[8]) is set to 1 or trim retry limitation count reached, this field will be cleared to 00 automatically. Note: HIRC1 auto trim cannot work normally inPower-down mode. These bits must be cleared before entering Power-down mode.
    0=Disable HIRC1 auto trim function; 2=Enable HIRC1 auto trim function and trim HIRC to 36 MHz
0x94 SYS_RC1TIEN — HIRC1 Trim Interrupt Enable Register
  [2] CLKEIEN — Clock Error Interrupt Enable Bit. This bit controls if CPU would get an interrupt while clock is inaccuracy during auto trim operation. If this bit is set to1, and CLKERRIF(SYS_IRC1TSTS[2]) is set during auto trim operation, an interrupt will be triggered to notify the clock frequency is inaccuracy.
    0=Disable CLKERRIF(SYS_IRC1TSTS[2]) status to trigger an interrupt to CPU; 1=Enable CLKERRIF(SYS_IRC1TSTS[2]) status to trigger an interrupt to CPU
  [1] TFAILIEN — Trim Failure Interrupt Enable Bit. This bit controls if an interrupt will be triggered while HIRC1 trim value update limitation count reached and HIRC1 frequency still not locked on target frequency set by FREQSEL(SYS_IRC1TCTL[1:0]). If this bit is high and TFAILIF(SYS_IRC1TSTS[1]) is set during auto trim operation, an interrupt will be triggered to notify that HIRC1 trim value update limitation count was reached.
    0=Disable TFAILIF(SYS_IRC1TSTS[1]) status to trigger an interrupt to CPU; 1=Enable TFAILIF(SYS_IRC1TSTS[1]) status to trigger an interrupt to CPU
0x98 SYS_RC1TISTS — HIRC1 Trim Interrupt Status Register
  [2] CLKERRIF — Clock Error Interrupt Status. When the frequency of 32.768 kHz external low speed crystal oscillator (LXT) or 36 MHz internal high speed RC oscillator (HIRC1) is shift larger to unreasonable value, this bit will be set and to be an indicate that clock frequency is inaccuracy. Once this bit is set to 1, the auto trim operation stopped and FREQSEL(SYS_IRC1TCTL[1:0]) will be cleared to 00 by hardware automatically if CESTOPEN(SYS_IRC1TCTL[8]) is set to 1. If this bit is set and CLKEIEN(SYS_IRC1TIEN[2]) is high, an interrupt will be triggered to notify the clock frequency is inaccuracy. Write 1 to clear this to 0.
    values as SYS_RC0TISTS.CLKERRIF
  [1] TFAILIF — Trim Failure Interrupt Status. This bit indicates that HIRC1 trim value update limitation count reached and the HIRC1 clock frequency still doesn't be locked. Once this bit is set, the auto trim operation stopped and FREQSEL(SYS_IRC1TCTL[1:0]) will be cleared to 00 by hardware automatically. If this bit is set and TFAILIEN(SYS_IRC1TIEN[1]) is high, an interrupt will be triggered to notify that HIRC1 trim value update limitation count was reached. Write 1 to clear this to 0.
    0=Trim value update limitation count does not reach; 1=Trim value update limitation count reached and HIRC1 frequency still not locked
  [0] FREQLOCK — HIRC1 Frequency Lock Status. This bit indicates the HIRC1 frequency is locked. This is a status bit and doesn't trigger any interrupt.
    0=The internal high-speed oscillator frequency doesn't lock at 36 MHz yet; 1=The internal high-speed oscillator frequency locked at 36 MHz
0xA0 SYS_MRCTCTL — MIRC Trim Control Register
  [8] CESTOPEN — Clock Error Stop Enable Bit. This bit is used to control if stop the MIRC trim operation when 32.768 kHz clock error is detected. If set this bit high and 32.768 kHz clock error detected, the status CLKERRIF (SYS_MIRCTISTS[2]) would be set high and MIRC trim operation was stopped. If this bit is low and 32.768 kHz clock error detected, the status CLKERRIF (SYS_MIRCTISTS[2]) would be set high and MIRC trim operation is continuously.
    values as SYS_RC0TCTL.CESTOPEN
  [7:6] RETRYCNT — Trim Value Update Limitation Count. This field defines that how many times the auto trim circuit will try to update the MIRC trim value before the frequency of MIRC locked. Once the MIRC locked, the internal trim value update counter will be reset. If the trim value update counter reached this limitation value and frequency of MIRC still doesn't lock, the auto trim operation will be disabled and FREQSEL (SYS_MIRCTCTL[1:0]) will be cleared to 00.
    values as SYS_RC0TCTL.RETRYCNT
  [5:4] LOOPSEL — Trim Calculation Loop Selection. This field defines that trim value calculation is based on how many 32.768 kHz clock. Note: For example, if LOOPSEL is set as 00, auto trim circuit will calculate trim value based on the average frequency difference in 4 32.768 kHz clock.
    values as SYS_RC0TCTL.LOOPSEL
  [1:0] FREQSEL — Trim Frequency Selection. This field indicates the target frequency of 4 MHz internal medium speed RC oscillator (MIRC) auto trim. During auto trim operation, if clock error detected with CESTOPEN (SYS_MIRCTCTL[8]) is set to 1 or trim retry limitation count reached, this field will be cleared to 00 automatically. Note:MIRC auto trim cannot work normally inPower downn mode. These bits must be cleared before entering Power-down mode.
    0=Disable MIRC auto trim function; 2=Enable MIRC auto trim function and trim HIRC to 4 MHz
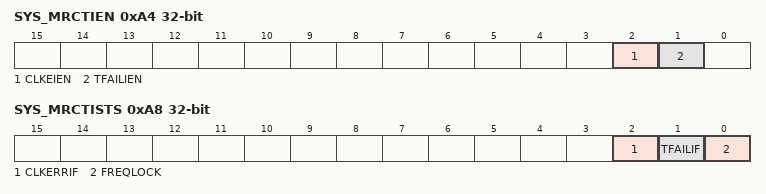
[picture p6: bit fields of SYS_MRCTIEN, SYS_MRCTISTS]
0xA4 SYS_MRCTIEN — MIRC Trim Interrupt Enable Register
  [2] CLKEIEN — Clock Error Interrupt Enable Bit. This bit controls if CPU would get an interrupt while clock is inaccuracy during auto trim operation. If this bit is set to1, and CLKERRIF(SYS_MIRCTSTS[2]) is set during auto trim operation, an interrupt will be triggered to notify the clock frequency is inaccuracy.
    0=Disable CLKERRIF(SYS_MIRCTSTS[2]) status to trigger an interrupt to CPU; 1=Enable CLKERRIF(SYS_MIRCTSTS[2]) status to trigger an interrupt to CPU
  [1] TFAILIEN — Trim Failure Interrupt Enable Bit. This bit controls if an interrupt will be triggered while MIRC trim value update limitation count reached and MIRC frequency still not locked on target frequency set by FREQSEL(SYS_MIRCTCTL[1:0]). If this bit is high and TFAILIF(SYS_MIRCTSTS[1]) is set during auto trim operation, an interrupt will be triggered to notify that MIRC trim value update limitation count was reached.
    0=Disable TFAILIF(SYS_MIRCTSTS[1]) status to trigger an interrupt to CPU; 1=Enable TFAILIF(SYS_MIRCTSTS[1]) status to trigger an interrupt to CPU
0xA8 SYS_MRCTISTS — MIRC Trim Interrupt Status Register
  [2] CLKERRIF — Clock Error Interrupt Status. When the frequency of 32.768 kHz external low speed crystal oscillator (LXT) or 4 MHz internal medium speed RC oscillator (MIRC) is shift larger to unreasonable value, this bit will be set and to be an indicate that clock frequency is inaccuracy. Once this bit is set to 1, the auto trim operation stopped and FREQSEL(SYS_MIRCTCTL[1:0]) will be cleared to 00 by hardware automatically if CESTOPEN(SYS_MIRCTCTL[8]) is set to 1. If this bit is set and CLKEIEN(SYS_MIRCTIEN[2]) is high, an interrupt will be triggered to notify the clock frequency is inaccuracy. Write 1 to clear this to 0.
    values as SYS_RC0TISTS.CLKERRIF
  [1] TFAILIF — Trim Failure Interrupt Status. This bit indicates that MIRC trim value update limitation count reached and the MIRC clock frequency still doesn't be locked. Once this bit is set, the auto trim operation stopped and FREQSEL(SYS_MIRCTCTL[1:0]) will be cleared to 00 by hardware automatically. If this bit is set and TFAILIEN(SYS_MIRCTIEN[1]) is high, an interrupt will be triggered to notify that MIRC trim value update limitation count was reached. Write 1 to clear this to 0.
    0=Trim value update limitation count does not reach; 1=Trim value update limitation count reached and MIRC frequency still not locked
  [0] FREQLOCK — MIRC Frequency Lock Status. This bit indicates the MIRC frequency is locked. This is a status bit and doesn't trigger any interrupt.
    0=The internal medium-speed oscillator frequency doesn't lock at 4 MHz yet; 1=The internal medium-speed oscillator frequency locked at 4 MHz
0x100 SYS_REGLCTL — Register Lock Control Register
  [7:0] REGLCTL — Register Lock Control Code (Write Only). Some registers have write-protection function. Writing these registers have to disable the protected function by writing the sequence value "59h", "16h", "88h" to this field. After this sequence is completed, the REGLCTL bit will be set to 1 and write-protection registers can be normal write. Register Lock Control Disable Index (Read Only)
    0=Write-protection Enabled for writing protected registers. Any write to the protected register is ignored; 1=Write-protection Disabled for writing protected registers
0x120 SYS_RPDBCLK reset not defined — Reset Pin Debounce Clock Selection Register
  [6] RSTPDBCLK — Reset Pin Debounce Clock Selection Bit. Before swtch clock, both clock sources must be enabled.
    0=HIRC2 is slected as reset pin debounce clock; 1=HIRC0 is slected as reset pin debounce clock.(.default)
